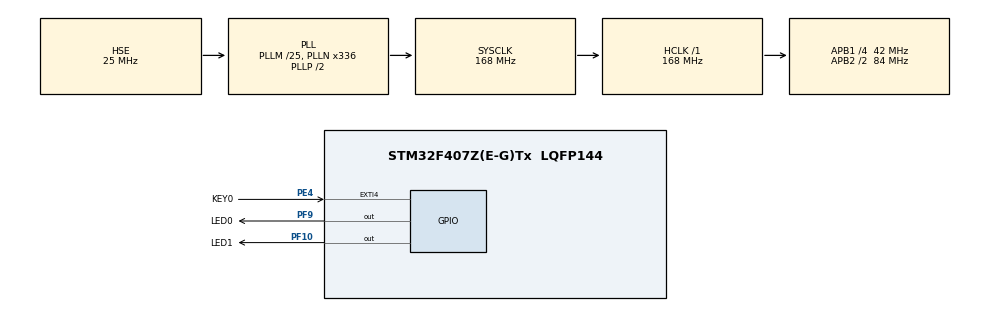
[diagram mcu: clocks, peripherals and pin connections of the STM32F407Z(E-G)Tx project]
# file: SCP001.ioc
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Mcu.Family=STM32F4
Mcu.Name=STM32F407Z(E-G)Tx
Mcu.Package=LQFP144
NVIC.EXTI4_IRQn=true\:0\:0\:false\:false\:true\:true\:true\:true
NVIC.PriorityGroup=NVIC_PRIORITYGROUP_4
PE4.GPIO_Label=KEY0
PE4.GPIO_ModeDefaultEXTI=GPIO_MODE_IT_FALLING
PE4.GPIO_PuPd=GPIO_PULLUP
PE4.Signal=GPXTI4
PF10.GPIO_Label=LED1
PF10.Signal=GPIO_Output
PF9.GPIO_Label=LED0
PF9.Signal=GPIO_Output
PH0-OSC_IN.Mode=HSE-External-Oscillator
PH0-OSC_IN.Signal=RCC_OSC_IN
PH1-OSC_OUT.Mode=HSE-External-Oscillator
PH1-OSC_OUT.Signal=RCC_OSC_OUT
ProjectManager.HeapSize=0x200
ProjectManager.StackSize=0x400
ProjectManager.TargetToolchain=MDK-ARM V5
RCC.48MHZClocksFreq_Value=84000000
RCC.AHBFreq_Value=168000000
RCC.APB1CLKDivider=RCC_HCLK_DIV4
RCC.APB1Freq_Value=42000000
RCC.APB1TimFreq_Value=84000000
RCC.APB2CLKDivider=RCC_HCLK_DIV2
RCC.APB2Freq_Value=84000000
RCC.APB2TimFreq_Value=168000000
RCC.CortexFreq_Value=168000000
RCC.HCLKFreq_Value=168000000
RCC.HSE_VALUE=25000000
RCC.HSI_VALUE=16000000
RCC.LSE_VALUE=32768
RCC.PLLM=25
RCC.PLLN=336
RCC.PLLSourceVirtual=RCC_PLLSOURCE_HSE
RCC.SYSCLKFreq_VALUE=168000000
RCC.SYSCLKSource=RCC_SYSCLKSOURCE_PLLCLK
RCC.VCOOutputFreq_Value=336000000
board=custom

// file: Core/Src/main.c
/* USER CODE BEGIN Header */
/**
  ******************************************************************************
  * @file           : main.c
  * @brief          : Main program body
  ******************************************************************************
  * @attention
  *
  * Copyright (c) 2026 STMicroelectronics.
  * All rights reserved.
  *
  * This software is licensed under terms that can be found in the LICENSE file
  * in the root directory of this software component.
  * If no LICENSE file comes with this software, it is provided AS-IS.
  *
  ******************************************************************************
  */
/* USER CODE END Header */
#include "main.h"
#include <stdint.h>

/* USER CODE BEGIN PTD */

typedef enum {
	GEAR_P=0,
	GEAR_R,
	GEAR_N,
	GEAR_D,
}GearState;

/* USER CODE END PTD */

/* USER CODE BEGIN PD */
#define DEBOUNCE_CYCLES 8400000UL
/* USER CODE END PD */

/* USER CODE BEGIN PV */

volatile GearState gear = GEAR_P;
static unsigned int last_interrupt_cycle=0;

/* USER CODE END PV */

void SystemClock_Config(void);
static void MX_GPIO_Init(void);
/* USER CODE BEGIN PFP */

static unsigned int DWT_GetCycle(void);
static void LED_Update(GearState state);
static void Gear_Shift(void );

/* USER CODE END PFP */

/* USER CODE BEGIN 0 */
/**
 * @brief  ??DWT????????
 * @retval DWT???
 */
static unsigned int DWT_GetCycle(void)
{
    return DWT->CYCCNT;
}

/**
 * @brief  ????????LED??
 * @param  state: ??????
 * @note   LED?????
 */
static void LED_Update(GearState state)
{
    switch(state)
    {
        case GEAR_P: // P?:LED0?,LED1?
            HAL_GPIO_WritePin(GPIOF, LED0_Pin, GPIO_PIN_RESET);
            HAL_GPIO_WritePin(GPIOF, LED1_Pin, GPIO_PIN_SET);
            break;
        case GEAR_R: // R?:LED0?,LED1?
            HAL_GPIO_WritePin(GPIOF, LED0_Pin, GPIO_PIN_SET);
            HAL_GPIO_WritePin(GPIOF, LED1_Pin, GPIO_PIN_RESET);
            break;
        case GEAR_N: // N?:????
            HAL_GPIO_WritePin(GPIOF, LED0_Pin, GPIO_PIN_SET);
            HAL_GPIO_WritePin(GPIOF, LED1_Pin, GPIO_PIN_SET);
            break;
        case GEAR_D: // D?:????
            HAL_GPIO_WritePin(GPIOF, LED0_Pin, GPIO_PIN_RESET);
            HAL_GPIO_WritePin(GPIOF, LED1_Pin, GPIO_PIN_RESET);
            break;
        default:
            break;
    }
}

/**
 * @brief  ?????? P?R?N?D?P
 * @retval ?
 */
static void Gear_Shift(void)
{
    gear++;
    if(gear > GEAR_D) // ????P?
    {
        gear = GEAR_P;
    }
    LED_Update(gear); // ???????LED
}
/* USER CODE END 0 */

int main(void)
{

  /* MCU Configuration--------------------------------------------------------*/

  /* Reset of all peripherals, Initializes the Flash interface and the Systick. */
  HAL_Init();

  /* Configure the system clock */
  SystemClock_Config();

  /* Initialize all configured peripherals */
  MX_GPIO_Init();
  /* USER CODE BEGIN 2 */
// 1. ??DWT???(Cortex-M4???????)
  CoreDebug->DEMCR |= CoreDebug_DEMCR_TRCENA_Msk; // ??DWT??
  DWT->CYCCNT = 0;                               // ?????
  DWT->CTRL |= DWT_CTRL_CYCCNTENA_Msk;           // ????

  // 2. ?????LED,????P?
  LED_Update(gear);

  /* USER CODE END 2 */

  /* Infinite loop */
  while (1)
  {

  }
}

void SystemClock_Config(void)
{
  RCC_OscInitTypeDef RCC_OscInitStruct = {0};
  RCC_ClkInitTypeDef RCC_ClkInitStruct = {0};

  /** Configure the main internal regulator output voltage
  */
  __HAL_RCC_PWR_CLK_ENABLE();
  __HAL_PWR_VOLTAGESCALING_CONFIG(PWR_REGULATOR_VOLTAGE_SCALE1);

  /** Initializes the RCC Oscillators according to the specified parameters
  * in the RCC_OscInitTypeDef structure.
  */
  RCC_OscInitStruct.OscillatorType = RCC_OSCILLATORTYPE_HSE;
  RCC_OscInitStruct.HSEState = RCC_HSE_ON;
  RCC_OscInitStruct.PLL.PLLState = RCC_PLL_ON;
  RCC_OscInitStruct.PLL.PLLSource = RCC_PLLSOURCE_HSE;
  RCC_OscInitStruct.PLL.PLLM = 25;
  RCC_OscInitStruct.PLL.PLLN = 336;
  RCC_OscInitStruct.PLL.PLLP = RCC_PLLP_DIV2;
  RCC_OscInitStruct.PLL.PLLQ = 4;
  if (HAL_RCC_OscConfig(&RCC_OscInitStruct) != HAL_OK)
  {
    Error_Handler();
  }

  /** Initializes the CPU, AHB and APB buses clocks
  */
  RCC_ClkInitStruct.ClockType = RCC_CLOCKTYPE_HCLK|RCC_CLOCKTYPE_SYSCLK
                              |RCC_CLOCKTYPE_PCLK1|RCC_CLOCKTYPE_PCLK2;
  RCC_ClkInitStruct.SYSCLKSource = RCC_SYSCLKSOURCE_PLLCLK;
  RCC_ClkInitStruct.AHBCLKDivider = RCC_SYSCLK_DIV1;
  RCC_ClkInitStruct.APB1CLKDivider = RCC_HCLK_DIV4;
  RCC_ClkInitStruct.APB2CLKDivider = RCC_HCLK_DIV2;

  if (HAL_RCC_ClockConfig(&RCC_ClkInitStruct, FLASH_LATENCY_5) != HAL_OK)
  {
    Error_Handler();
  }
}

static void MX_GPIO_Init(void)
{
  GPIO_InitTypeDef GPIO_InitStruct = {0};

  /* GPIO Ports Clock Enable */
  __HAL_RCC_GPIOE_CLK_ENABLE();
  __HAL_RCC_GPIOF_CLK_ENABLE();
  __HAL_RCC_GPIOH_CLK_ENABLE();

  /*Configure GPIO pin Output Level */
  HAL_GPIO_WritePin(GPIOF, LED0_Pin|LED1_Pin, GPIO_PIN_RESET);

  /*Configure GPIO pin : KEY0_Pin */
  GPIO_InitStruct.Pin = KEY0_Pin;
  GPIO_InitStruct.Mode = GPIO_MODE_IT_FALLING;
  GPIO_InitStruct.Pull = GPIO_PULLUP;
  HAL_GPIO_Init(KEY0_GPIO_Port, &GPIO_InitStruct);

  /*Configure GPIO pins : LED0_Pin LED1_Pin */
  GPIO_InitStruct.Pin = LED0_Pin|LED1_Pin;
  GPIO_InitStruct.Mode = GPIO_MODE_OUTPUT_PP;
  GPIO_InitStruct.Pull = GPIO_NOPULL;
  GPIO_InitStruct.Speed = GPIO_SPEED_FREQ_LOW;
  HAL_GPIO_Init(GPIOF, &GPIO_InitStruct);

  /* EXTI interrupt init*/
  HAL_NVIC_SetPriority(EXTI4_IRQn, 0, 0);
  HAL_NVIC_EnableIRQ(EXTI4_IRQn);

}

/* USER CODE BEGIN 4 */
/**
 * @brief  GPIO????????(HAL????,?????????)
 * @param  GPIO_Pin: ???????
 */
void HAL_GPIO_EXTI_Callback(uint16_t GPIO_Pin)
{
    unsigned int current_cycle = DWT_GetCycle(); // ????DWT???

    // ?????KEY0(PE4)????
    if(GPIO_Pin == KEY0_Pin)
    {
        // DWT??:????50ms????????
        if((current_cycle - last_interrupt_cycle) > DEBOUNCE_CYCLES)
        {
            last_interrupt_cycle = current_cycle; // ??????
            Gear_Shift();                          // ??????
        }
    }
}
/* USER CODE END 4 */

void Error_Handler(void)
{
  __disable_irq();
  while (1)
  {
  }
}
